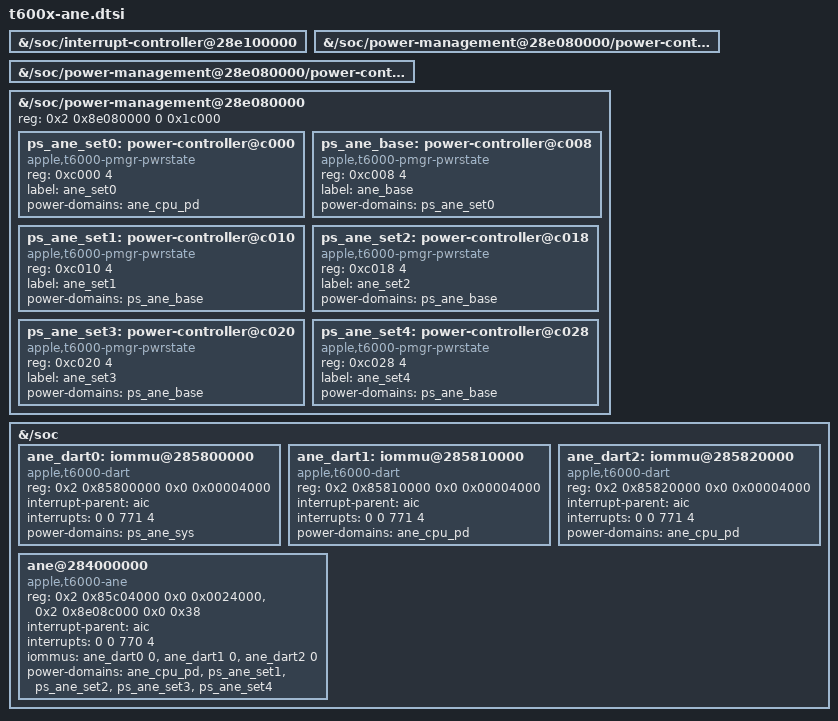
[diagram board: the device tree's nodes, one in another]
// SPDX-License-Identifier: GPL-2.0+ OR MIT
/*
 * The die-0 ANE of T600x (T6000 M1 Pro, T6001 M1 Max, T6002 M1 Ultra), for
 * the overlays t6000-ane.dts, t6001-ane.dts and t6002-ane.dts.
 *
 * The nodes are those of the lab overlay ane/t6001-j316c-set-domains.dts,
 * which bound ane.ko and ran exact fp16 programs on the M1 Max host. Three
 * facts make it safe on every stock T600x tree:
 *  - AIC and ane_sys@268 are reached by path. The lab file uses their raw
 *    phandles 0x13 and 0x18, which are right only while the kernel keeps them.
 *  - The pmgr window is 0x1c000. The lab file sets 0x14000 to cover SET0 at
 *    0xc000. linux-asahi 7.1.13 ships 0x4000, but linux-aurora 7.1.12 already
 *    ships 0x1c000 with a child past 0x14000, so 0x14000 would cut that off.
 *  - The node names its SET window ("set", pmgr + 0xc000, the 0x38 bytes
 *    ane.ko maps): the driver takes the SET base from the node and keeps the
 *    descriptor constant only for trees without the window
 *    (docs/ultra-die1.md §2). The value is the proven die-0 base.
 * No set5@c030: it is past ADT range1 0xc02c, and the lab overlay records a
 * genpd timeout with it in the ane power-domains. aurora-silicon/linux #155
 * dropped it too.
 * The power states set status "okay": #155 ships them at the same paths,
 * disabled, on every T600x but the M1 Max. On such a kernel omarchy-ane-dt
 * applies the overlay, fdtoverlay merges each node into the kernel's, and a
 * node without a status here would stay disabled
 * (receipts/2026-10-01-ane-dt-disabled-nodes).
 *
 * T6000 and T6002 have the same die-0 values as T6001: in the macOS 13.5
 * ADTs (j314s, j316s, j375d against j316c) /arm-io/ane0 has reg
 * 0x284000000+0x2000000 and 0x28e080000+0xc02c and interrupt 770,
 * /arm-io/dart-ane0 has reg 0x285800000, 0x285810000, 0x285820000 and
 * interrupt 771, and pmgr has ANE_SYS at 0x268 and ANE_SYS_CPU at 0x2c8.
 * linux-asahi 7.1.13 builds all three from the same t600x-die0.dtsi and
 * t600x-pmgr.dtsi.
 * Community rows (receipts/2026-10-01-community-rows; row = submission sha256
 * prefix): the M1 Ultra macOS 26.6.2 IORegistry (J375d: 755c2d8d3b9a,
 * ffe77ec70b57, 14fbcbe67589, 5e75a04c9727, 869e1c8ba779) has the same die-0
 * ane0 reg, interrupt 770, dart-ane0 reg and interrupt 771. The T6000 Linux
 * rows (j314s: c901d2bb47ba, 1c239648b330; j316s: 8bdc4c196309, fbc20029b7fd)
 * have the AIC path and ane_sys@268 and ane_sys_cpu@2c8 used here, and pmgr
 * reg 0x4000. No M1 Pro macOS row exists.
 */

/ {
	fragment@0 {
		target-path = "/soc/interrupt-controller@28e100000";
		aic: __overlay__ {
		};
	};

	fragment@1 {
		target-path = "/soc/power-management@28e080000/power-controller@268";
		ps_ane_sys: __overlay__ {
		};
	};

	fragment@2 {
		target-path = "/soc/power-management@28e080000/power-controller@2c8";
		ane_cpu_pd: __overlay__ {
		};
	};

	fragment@3 {
		target-path = "/soc/power-management@28e080000";

		__overlay__ {
			reg = <0x2 0x8e080000 0 0x1c000>;

			ps_ane_set0: power-controller@c000 {
				compatible = "apple,t6000-pmgr-pwrstate", "apple,pmgr-pwrstate";
				reg = <0xc000 4>;
				#power-domain-cells = <0>;
				#reset-cells = <0>;
				label = "ane_set0";
				power-domains = <&ane_cpu_pd>;
				status = "okay";
			};

			ps_ane_base: power-controller@c008 {
				compatible = "apple,t6000-pmgr-pwrstate", "apple,pmgr-pwrstate";
				reg = <0xc008 4>;
				#power-domain-cells = <0>;
				#reset-cells = <0>;
				label = "ane_base";
				power-domains = <&ps_ane_set0>;
				status = "okay";
			};

			ps_ane_set1: power-controller@c010 {
				compatible = "apple,t6000-pmgr-pwrstate", "apple,pmgr-pwrstate";
				reg = <0xc010 4>;
				#power-domain-cells = <0>;
				#reset-cells = <0>;
				label = "ane_set1";
				power-domains = <&ps_ane_base>;
				status = "okay";
			};

			ps_ane_set2: power-controller@c018 {
				compatible = "apple,t6000-pmgr-pwrstate", "apple,pmgr-pwrstate";
				reg = <0xc018 4>;
				#power-domain-cells = <0>;
				#reset-cells = <0>;
				label = "ane_set2";
				power-domains = <&ps_ane_base>;
				status = "okay";
			};

			ps_ane_set3: power-controller@c020 {
				compatible = "apple,t6000-pmgr-pwrstate", "apple,pmgr-pwrstate";
				reg = <0xc020 4>;
				#power-domain-cells = <0>;
				#reset-cells = <0>;
				label = "ane_set3";
				power-domains = <&ps_ane_base>;
				status = "okay";
			};

			ps_ane_set4: power-controller@c028 {
				compatible = "apple,t6000-pmgr-pwrstate", "apple,pmgr-pwrstate";
				reg = <0xc028 4>;
				#power-domain-cells = <0>;
				#reset-cells = <0>;
				label = "ane_set4";
				power-domains = <&ps_ane_base>;
				status = "okay";
			};
		};
	};

	fragment@4 {
		target-path = "/soc";

		__overlay__ {
			ane_dart0: iommu@285800000 {
				compatible = "apple,t6000-dart";
				reg = <0x2 0x85800000 0x0 0x00004000>;
				#iommu-cells = <1>;
				interrupt-parent = <&aic>;
				interrupts = <0 0 771 4>;
				power-domains = <&ps_ane_sys>;
				status = "okay";
			};

			ane_dart1: iommu@285810000 {
				compatible = "apple,t6000-dart";
				reg = <0x2 0x85810000 0x0 0x00004000>;
				#iommu-cells = <1>;
				interrupt-parent = <&aic>;
				interrupts = <0 0 771 4>;
				power-domains = <&ane_cpu_pd>;
				status = "okay";
			};

			ane_dart2: iommu@285820000 {
				compatible = "apple,t6000-dart";
				reg = <0x2 0x85820000 0x0 0x00004000>;
				#iommu-cells = <1>;
				interrupt-parent = <&aic>;
				interrupts = <0 0 771 4>;
				power-domains = <&ane_cpu_pd>;
				status = "okay";
			};

			ane@284000000 {
				compatible = "apple,t6000-ane";
				reg-names = "engine", "set";
				reg = <0x2 0x85c04000 0x0 0x0024000>,
				      <0x2 0x8e08c000 0x0 0x38>;
				interrupt-parent = <&aic>;
				interrupt-names = "ane";
				interrupts = <0 0 770 4>;
				iommus = <&ane_dart0 0>, <&ane_dart1 0>, <&ane_dart2 0>;
				power-domains = <&ane_cpu_pd>,
						<&ps_ane_set1>,
						<&ps_ane_set2>,
						<&ps_ane_set3>,
						<&ps_ane_set4>;
				status = "okay";
			};
		};
	};
};
